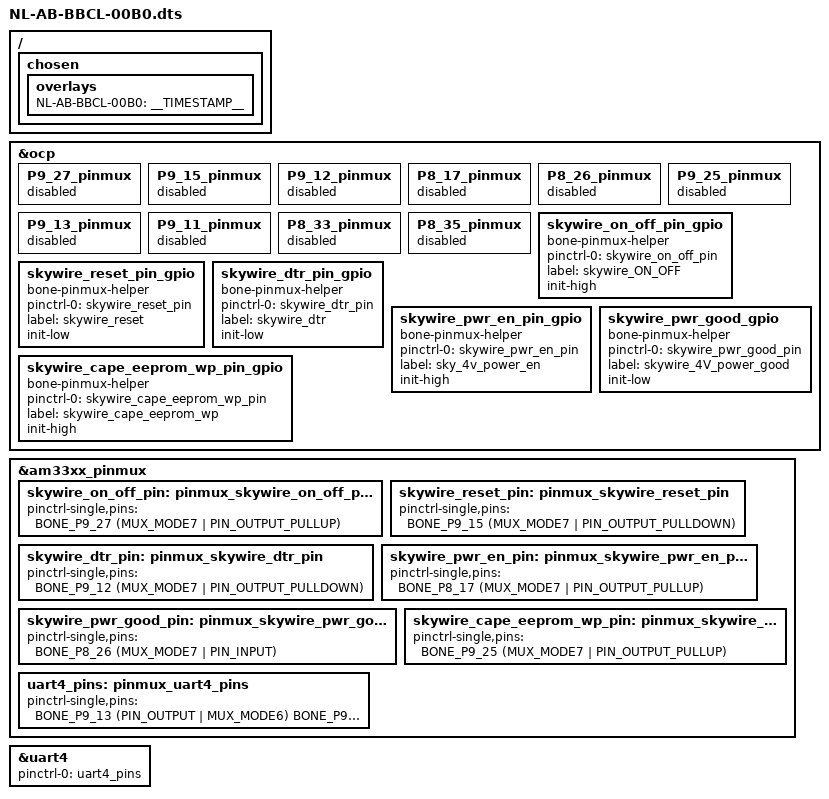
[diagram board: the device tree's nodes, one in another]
/*
 * Copyright (C) 2017 nimbelink.com, MIT License
 *
 * Permission is hereby granted, free of charge, to any person obtaining a copy of this software
 * and associated documentation files (the "Software"), to deal in the Software without restriction,
 * including without limitation the rights to use, copy, modify, merge, publish, distribute,
 * sublicense, and/or sell copies of the Software, and to permit persons to whom the Software is
 * furnished to do so, subject to the following conditions:
 *
 * The above copyright notice and this permission notice shall be included in all copies or
 * substantial portions of the Software.
 *
 * THE SOFTWARE IS PROVIDED "AS IS", WITHOUT WARRANTY OF ANY KIND, EXPRESS OR IMPLIED, INCLUDING
 * BUT NOT LIMITED TO THE WARRANTIES OF MERCHANTABILITY, FITNESS FOR A PARTICULAR PURPOSE AND
 * NONINFRINGEMENT. IN NO EVENT SHALL THE AUTHORS OR COPYRIGHT HOLDERS BE LIABLE FOR ANY CLAIM,
 * DAMAGES OR OTHER LIABILITY, WHETHER IN AN ACTION OF CONTRACT, TORT OR OTHERWISE, ARISING FROM,
 * OUT OF OR IN CONNECTION WITH THE SOFTWARE OR THE USE OR OTHER DEALINGS IN THE SOFTWARE.
 */

/dts-v1/;
/plugin/;

#include <dt-bindings/board/am335x-bbw-bbb-base.h>
#include <dt-bindings/pinctrl/am33xx.h>

/ {
	/*
	 * Helper to show loaded overlays under: /proc/device-tree/chosen/overlays/
	 */
	fragment@0 {
		target-path="/";
		__overlay__ {

			chosen {
				overlays {
					NL-AB-BBCL-00B0 = __TIMESTAMP__;
				};
			};
		};
	};

	/*
	 * Free up the pins used by the cape from the pinmux helpers.
	 */
	fragment@1 {
		target = <&ocp>;
		__overlay__ {
			P9_27_pinmux { status = "disabled"; };
			P9_15_pinmux { status = "disabled"; };
			P9_12_pinmux { status = "disabled"; };
			P8_17_pinmux { status = "disabled"; };
			P8_26_pinmux { status = "disabled"; };
			P9_25_pinmux { status = "disabled"; };
			P9_13_pinmux { status = "disabled"; };
			P9_11_pinmux { status = "disabled"; };
			P8_33_pinmux { status = "disabled"; };
			P8_35_pinmux { status = "disabled"; };
		};
	};

	fragment@2 {
		target = <&am33xx_pinmux>;
		__overlay__ {
			skywire_on_off_pin: pinmux_skywire_on_off_pin {
				pinctrl-single,pins = <
					BONE_P9_27 (MUX_MODE7 | PIN_OUTPUT_PULLUP)
				>;
			};

			skywire_reset_pin: pinmux_skywire_reset_pin {
				pinctrl-single,pins = <
					BONE_P9_15 (MUX_MODE7 | PIN_OUTPUT_PULLDOWN)
				>;
			};

			skywire_dtr_pin: pinmux_skywire_dtr_pin {
				pinctrl-single,pins = <
					BONE_P9_12 (MUX_MODE7 | PIN_OUTPUT_PULLDOWN)
				>;
			};

			skywire_pwr_en_pin: pinmux_skywire_pwr_en_pin {
				pinctrl-single,pins = <
					BONE_P8_17 (MUX_MODE7 | PIN_OUTPUT_PULLUP)
				>;
			};

			skywire_pwr_good_pin: pinmux_skywire_pwr_good_pin {
				pinctrl-single,pins = <
					BONE_P8_26 (MUX_MODE7 | PIN_INPUT)
				>;
			};

			skywire_cape_eeprom_wp_pin: pinmux_skywire_cape_eeprom_wp_pin {
				pinctrl-single,pins = <
					BONE_P9_25 (MUX_MODE7 | PIN_OUTPUT_PULLUP)
				>;
			};

			uart4_pins: pinmux_uart4_pins {
				pinctrl-single,pins = <
					BONE_P9_13 (PIN_OUTPUT | MUX_MODE6) /* gpmc_wpn.uart4_txd_mux2 */
					BONE_P9_11 (PIN_INPUT | MUX_MODE6) /* gpmc_wait0.uart4_rxd_mux2 */
					BONE_P8_33 (PIN_OUTPUT | MUX_MODE6)
					BONE_P8_35 (PIN_INPUT | MUX_MODE6)
					>;
			};
		};
	};

	fragment@3 {
		target = <&uart4>; 
		__overlay__ {
			pinctrl-names = "default";
			pinctrl-0 = <&uart4_pins>;
			status = "okay";
		};
	};

	fragment@4 {
		target = <&ocp>;
		__overlay__ {

			skywire_on_off_pin_gpio {
				compatible = "bone-pinmux-helper";
				pinctrl-names = "default";
				pinctrl-0 = <&skywire_on_off_pin>;
				status = "okay";
				label = "skywire_ON_OFF";
				init-high;
			};

			skywire_reset_pin_gpio {
				compatible = "bone-pinmux-helper";
				pinctrl-names = "default";
				pinctrl-0 = <&skywire_reset_pin>;
				status = "okay";
				label = "skywire_reset";
				init-low;
			};

			skywire_dtr_pin_gpio {
				compatible = "bone-pinmux-helper";
				pinctrl-names = "default";
				pinctrl-0 = <&skywire_dtr_pin>;
				status = "okay";
				label = "skywire_dtr";
				init-low;
			};

			skywire_pwr_en_pin_gpio {
				compatible = "bone-pinmux-helper";
				pinctrl-names = "default";
				pinctrl-0 = <&skywire_pwr_en_pin>;
				status = "okay";
				label = "sky_4v_power_en";
				init-high;
			};

			skywire_pwr_good_gpio {
				compatible = "bone-pinmux-helper";
				pinctrl-names = "default";
				pinctrl-0 = <&skywire_pwr_good_pin>;
				status = "okay";
				label = "skywire_4V_power_good";
				init-low;
			};

			skywire_cape_eeprom_wp_pin_gpio {
				compatible = "bone-pinmux-helper";
				pinctrl-names = "default";
				pinctrl-0 = <&skywire_cape_eeprom_wp_pin>;
				status = "okay";
				label = "skywire_cape_eeprom_wp";
				init-high;
			};
		};
	};
};

